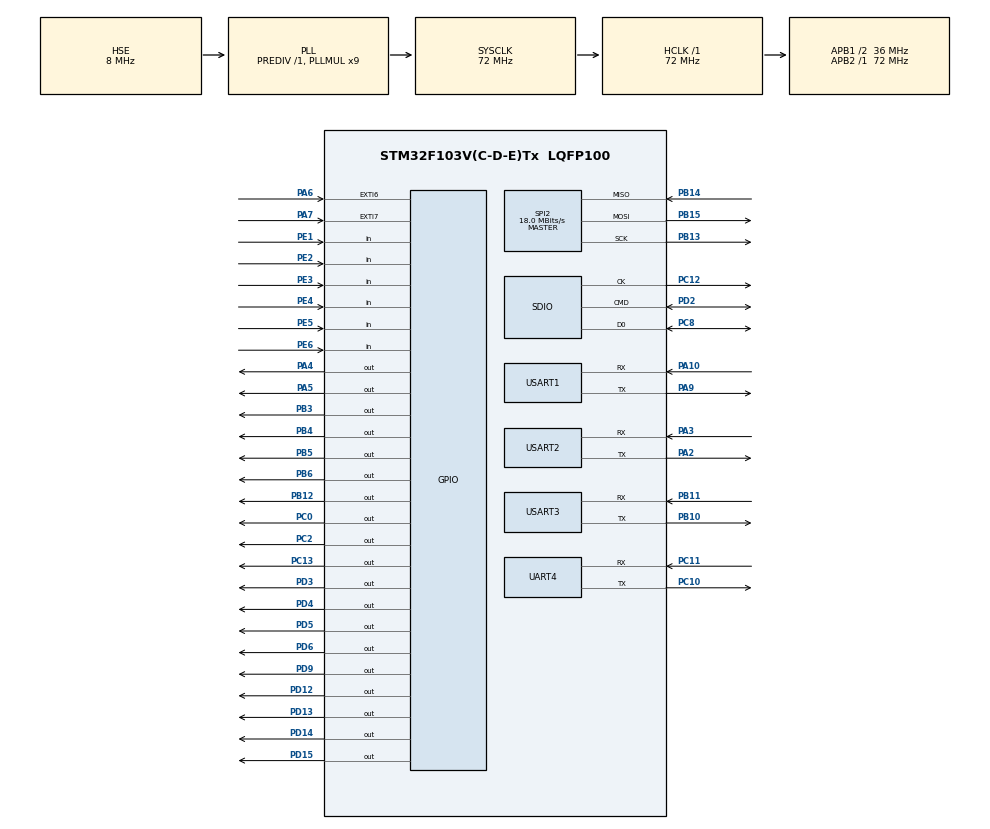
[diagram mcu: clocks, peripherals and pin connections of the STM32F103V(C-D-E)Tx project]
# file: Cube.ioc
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ADC1.Channel-0\#ChannelRegularConversion=ADC_CHANNEL_TEMPSENSOR
ADC1.ContinuousConvMode=DISABLE
ADC1.DataAlign=ADC_DATAALIGN_RIGHT
ADC1.DiscontinuousConvMode=DISABLE
ADC1.EnableAnalogWatchDog=false
ADC1.EnableRegularConversion=ENABLE
ADC1.ExternalTrigConv=ADC_SOFTWARE_START
ADC1.InjNumberOfConversion=0
ADC1.NbrOfConversion=1
ADC1.NbrOfConversionFlag=1
ADC1.Rank-0\#ChannelRegularConversion=1
ADC1.SamplingTime-0\#ChannelRegularConversion=ADC_SAMPLETIME_7CYCLES_5
ADC1.ScanConvMode=ADC_SCAN_DISABLE
ADC1.master=1
Mcu.Family=STM32F1
Mcu.Name=STM32F103V(C-D-E)Tx
Mcu.Package=LQFP100
NVIC.ADC1_2_IRQn=true\:0\:0\:false\:false\:true\:true
NVIC.EXTI9_5_IRQn=true\:5\:0\:true\:false\:true\:true
NVIC.PriorityGroup=NVIC_PRIORITYGROUP_4
NVIC.RTC_Alarm_IRQn=true\:0\:0\:false\:false\:true\:true
NVIC.RTC_IRQn=true\:0\:0\:false\:false\:true\:true
NVIC.TimeBase=TIM2_IRQn
NVIC.TimeBaseIP=TIM2
OSC_IN.Mode=HSE-External-Oscillator
OSC_IN.Signal=RCC_OSC_IN
OSC_OUT.Mode=HSE-External-Oscillator
OSC_OUT.Signal=RCC_OSC_OUT
PA10.Mode=Asynchronous
PA10.Signal=USART1_RX
PA13.Mode=Serial_Wire
PA13.Signal=SYS_JTMS-SWDIO
PA14.Mode=Serial_Wire
PA14.Signal=SYS_JTCK-SWCLK
PA2.Mode=Asynchronous
PA2.Signal=USART2_TX
PA3.Mode=Asynchronous
PA3.Signal=USART2_RX
PA4.Signal=GPIO_Output
PA5.Signal=GPIO_Output
PA6.GPIO_PuPd=GPIO_NOPULL
PA6.Signal=GPXTI6
PA7.GPIO_PuPd=GPIO_NOPULL
PA7.Signal=GPXTI7
PA9.Mode=Asynchronous
PA9.Signal=USART1_TX
PB10.Mode=Asynchronous
PB10.Signal=USART3_TX
PB11.Mode=Asynchronous
PB11.Signal=USART3_RX
PB12.Signal=GPIO_Output
PB13.Mode=Full_Duplex_Master
PB13.Signal=SPI2_SCK
PB14.Mode=Full_Duplex_Master
PB14.Signal=SPI2_MISO
PB15.Mode=Full_Duplex_Master
PB15.Signal=SPI2_MOSI
PB3.Signal=GPIO_Output
PB4.Signal=GPIO_Output
PB5.Signal=GPIO_Output
PB6.Signal=GPIO_Output
PC0.Signal=GPIO_Output
PC10.Mode=Asynchronous
PC10.Signal=UART4_TX
PC11.Mode=Asynchronous
PC11.Signal=UART4_RX
PC12.Mode=SD_1_bit
PC12.Signal=SDIO_CK
PC13-TAMPER-RTC.Signal=GPIO_Output
PC14-OSC32_IN.Mode=LSE-External-Oscillator
PC14-OSC32_IN.Signal=RCC_OSC32_IN
PC15-OSC32_OUT.Mode=LSE-External-Oscillator
PC15-OSC32_OUT.Signal=RCC_OSC32_OUT
PC2.Signal=GPIO_Output
PC8.Mode=SD_1_bit
PC8.Signal=SDIO_D0
PD12.GPIO_ModeDefaultOutputPP=GPIO_MODE_OUTPUT_PP
PD12.GPIO_Speed=GPIO_SPEED_FREQ_LOW
PD12.PinState=GPIO_PIN_RESET
PD12.Signal=GPIO_Output
PD13.GPIO_ModeDefaultOutputPP=GPIO_MODE_OUTPUT_PP
PD13.GPIO_Speed=GPIO_SPEED_FREQ_LOW
PD13.PinState=GPIO_PIN_RESET
PD13.Signal=GPIO_Output
PD14.Signal=GPIO_Output
PD15.Signal=GPIO_Output
PD2.Mode=SD_1_bit
PD2.Signal=SDIO_CMD
PD3.Signal=GPIO_Output
PD4.Signal=GPIO_Output
PD5.Signal=GPIO_Output
PD6.Signal=GPIO_Output
PD9.Signal=GPIO_Output
PE1.Signal=GPIO_Input
PE2.Signal=GPIO_Input
PE3.Signal=GPIO_Input
PE4.Signal=GPIO_Input
PE5.Signal=GPIO_Input
PE6.Signal=GPIO_Input
ProjectManager.HeapSize=0x800
ProjectManager.StackSize=0x800
ProjectManager.TargetToolchain=TrueSTUDIO
RCC.ADCPresc=RCC_ADCPCLK2_DIV6
RCC.AHBFreq_Value=72000000
RCC.APB1CLKDivider=RCC_HCLK_DIV2
RCC.APB1Freq_Value=36000000
RCC.APB1TimFreq_Value=72000000
RCC.APB2Freq_Value=72000000
RCC.APB2TimFreq_Value=72000000
RCC.HCLKFreq_Value=72000000
RCC.PLLMUL=RCC_PLL_MUL9
RCC.PLLSourceVirtual=RCC_PLLSOURCE_HSE
RCC.RTCClockSelection=RCC_RTCCLKSOURCE_LSE
RCC.SYSCLKFreq_VALUE=72000000
RCC.SYSCLKSource=RCC_SYSCLKSOURCE_PLLCLK
RCC.USBFreq_Value=48000000
RCC.USBPrescaler=RCC_USBCLKSOURCE_PLL_DIV1_5
RTC.Date=14
RTC.Hours=1
RTC.Minutes=54
RTC.Month=RTC_MONTH_AUGUST
RTC.Year=17
SPI2.BaudRatePrescaler=SPI_BAUDRATEPRESCALER_2
SPI2.CalculateBaudRate=18.0 MBits/s
SPI2.Direction=SPI_DIRECTION_2LINES
SPI2.Mode=SPI_MODE_MASTER
SPI2.VirtualType=VM_MASTER
TIM1.ClockDivision=TIM_CLOCKDIVISION_DIV2
TIM1.Period=65535
TIM1.Prescaler=0
UART4.VirtualMode=Asynchronous
USART1.VirtualMode=VM_ASYNC
USART2.VirtualMode=VM_ASYNC
USART3.VirtualMode=VM_ASYNC
VP_ADC1_TempSens_Input.Mode=IN-TempSens
VP_RTC_No_RTC_Output.Mode=RTC_OUT_NO
VP_RTC_VS_RTC_Activate.Mode=RTC_Enabled
VP_RTC_VS_RTC_Calendar.Mode=RTC_Calendar
VP_SYS_VS_tim2.Mode=TIM2
VP_TIM1_VS_ClockSourceINT.Mode=Internal
VP_TIM1_VS_ClockSourceITR.Mode=TriggerSource_ITR0
VP_TIM1_VS_ControllerModeTrigger.Mode=Trigger Mode
board=Cube

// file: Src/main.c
/**
  ******************************************************************************
  * File Name          : main.c
  * Description        : Main program body
  ******************************************************************************
  ** This notice applies to any and all portions of this file
  * that are not between comment pairs USER CODE BEGIN and
  * USER CODE END. Other portions of this file, whether
  * inserted by the user or by software development tools
  * are owned by their respective copyright owners.
  *
  * COPYRIGHT(c) 2017 STMicroelectronics
  *
  * Redistribution and use in source and binary forms, with or without modification,
  * are permitted provided that the following conditions are met:
  *   1. Redistributions of source code must retain the above copyright notice,
  *      this list of conditions and the following disclaimer.
  *   2. Redistributions in binary form must reproduce the above copyright notice,
  *      this list of conditions and the following disclaimer in the documentation
  *      and/or other materials provided with the distribution.
  *   3. Neither the name of STMicroelectronics nor the names of its contributors
  *      may be used to endorse or promote products derived from this software
  *      without specific prior written permission.
  *
  * THIS SOFTWARE IS PROVIDED BY THE COPYRIGHT HOLDERS AND CONTRIBUTORS "AS IS"
  * AND ANY EXPRESS OR IMPLIED WARRANTIES, INCLUDING, BUT NOT LIMITED TO, THE
  * IMPLIED WARRANTIES OF MERCHANTABILITY AND FITNESS FOR A PARTICULAR PURPOSE ARE
  * DISCLAIMED. IN NO EVENT SHALL THE COPYRIGHT HOLDER OR CONTRIBUTORS BE LIABLE
  * FOR ANY DIRECT, INDIRECT, INCIDENTAL, SPECIAL, EXEMPLARY, OR CONSEQUENTIAL
  * DAMAGES (INCLUDING, BUT NOT LIMITED TO, PROCUREMENT OF SUBSTITUTE GOODS OR
  * SERVICES; LOSS OF USE, DATA, OR PROFITS; OR BUSINESS INTERRUPTION) HOWEVER
  * CAUSED AND ON ANY THEORY OF LIABILITY, WHETHER IN CONTRACT, STRICT LIABILITY,
  * OR TORT (INCLUDING NEGLIGENCE OR OTHERWISE) ARISING IN ANY WAY OUT OF THE USE
  * OF THIS SOFTWARE, EVEN IF ADVISED OF THE POSSIBILITY OF SUCH DAMAGE.
  *
  ******************************************************************************
  */
#include "main.h"
#include "stm32f1xx_hal.h"
#include "adc.h"
#include "rtc.h"
#include "sdio.h"
#include "spi.h"
#include "tim.h"
#include "usart.h"
#include "gpio.h"

/* USER CODE BEGIN Includes */
#include "config.h"
#include "hyetal.h"

/* USER CODE END Includes */

/* USER CODE BEGIN PV */
/* Private variables ---------------------------------------------------------*/

/* USER CODE END PV */

void SystemClock_Config(void);

/* USER CODE BEGIN PFP */
/* Private function prototypes -----------------------------------------------*/

/* USER CODE END PFP */

int main(void)
{

  /* MCU Configuration----------------------------------------------------------*/

  /* Reset of all peripherals, Initializes the Flash interface and the Systick. */
  HAL_Init();

  /* Configure the system clock */
  SystemClock_Config();

  /* Initialize all configured peripherals */
  MX_GPIO_Init();
  MX_RTC_Init();
  MX_TIM1_Init();
  MX_ADC1_Init();
  MX_SPI2_Init();
  MX_UART4_Init();
  MX_USART3_UART_Init();
  MX_USART2_UART_Init();
  MX_USART1_UART_Init();
  MX_SDIO_SD_Init();

  /* Infinite loop */
  while (1)
  {
	  calculate_5minute_rainFall();

  }

}

/** System Clock Configuration
*/
void SystemClock_Config(void)
{

  RCC_OscInitTypeDef RCC_OscInitStruct;
  RCC_ClkInitTypeDef RCC_ClkInitStruct;
  RCC_PeriphCLKInitTypeDef PeriphClkInit;

    /**Initializes the CPU, AHB and APB busses clocks
    */
  RCC_OscInitStruct.OscillatorType = RCC_OSCILLATORTYPE_HSE|RCC_OSCILLATORTYPE_LSE;
  RCC_OscInitStruct.HSEState = RCC_HSE_ON;
  RCC_OscInitStruct.HSEPredivValue = RCC_HSE_PREDIV_DIV1;
  RCC_OscInitStruct.LSEState = RCC_LSE_ON;
  RCC_OscInitStruct.HSIState = RCC_HSI_ON;
  RCC_OscInitStruct.PLL.PLLState = RCC_PLL_ON;
  RCC_OscInitStruct.PLL.PLLSource = RCC_PLLSOURCE_HSE;
  RCC_OscInitStruct.PLL.PLLMUL = RCC_PLL_MUL9;
  if (HAL_RCC_OscConfig(&RCC_OscInitStruct) != HAL_OK)
  {
    _Error_Handler(__FILE__, __LINE__);
  }

    /**Initializes the CPU, AHB and APB busses clocks
    */
  RCC_ClkInitStruct.ClockType = RCC_CLOCKTYPE_HCLK|RCC_CLOCKTYPE_SYSCLK
                              |RCC_CLOCKTYPE_PCLK1|RCC_CLOCKTYPE_PCLK2;
  RCC_ClkInitStruct.SYSCLKSource = RCC_SYSCLKSOURCE_PLLCLK;
  RCC_ClkInitStruct.AHBCLKDivider = RCC_SYSCLK_DIV1;
  RCC_ClkInitStruct.APB1CLKDivider = RCC_HCLK_DIV2;
  RCC_ClkInitStruct.APB2CLKDivider = RCC_HCLK_DIV1;

  if (HAL_RCC_ClockConfig(&RCC_ClkInitStruct, FLASH_LATENCY_2) != HAL_OK)
  {
    _Error_Handler(__FILE__, __LINE__);
  }

  PeriphClkInit.PeriphClockSelection = RCC_PERIPHCLK_RTC|RCC_PERIPHCLK_ADC;
  PeriphClkInit.RTCClockSelection = RCC_RTCCLKSOURCE_LSE;
  PeriphClkInit.AdcClockSelection = RCC_ADCPCLK2_DIV6;
  if (HAL_RCCEx_PeriphCLKConfig(&PeriphClkInit) != HAL_OK)
  {
    _Error_Handler(__FILE__, __LINE__);
  }

    /**Configure the Systick interrupt time
    */
  HAL_SYSTICK_Config(HAL_RCC_GetHCLKFreq()/1000);

    /**Configure the Systick
    */
  HAL_SYSTICK_CLKSourceConfig(SYSTICK_CLKSOURCE_HCLK);

  /* SysTick_IRQn interrupt configuration */
  HAL_NVIC_SetPriority(SysTick_IRQn, 0, 0);
}

void HAL_TIM_PeriodElapsedCallback(TIM_HandleTypeDef *htim)
{
  if (htim->Instance == TIM2) {
    HAL_IncTick();
  }
}

void _Error_Handler(char * file, int line)
{
  while(1)
  {
  }
}

/************************ (C) COPYRIGHT STMicroelectronics *****END OF FILE****/
